# apollo2 register map
Vendor: Ambiq Micro; Series: Apollo; File version: 1.0
CPU: CM4 r1p0, little endian, MPU, FPU, 3 interrupt priority bits
Registers are 32-bit, read-write, reset 0x0 unless marked. A register's access mark holds for its fields unless they carry their own. Offsets are from the block's base; [hi:lo] are bit positions; {n}, {i} and the like mark numbered series; 'fields as' and 'values as' point back to an identical list.

## IOMSTR0 — I2C/SPI Master
Base 0x50004000
Same registers: IOMSTR1 0x50005000, IOMSTR2 0x50006000, IOMSTR3 0x50007000, IOMSTR4 0x50008000, IOMSTR5 0x50009000
0x00 FIFO — FIFO Access Port
  [31:0] FIFO — FIFO access port.
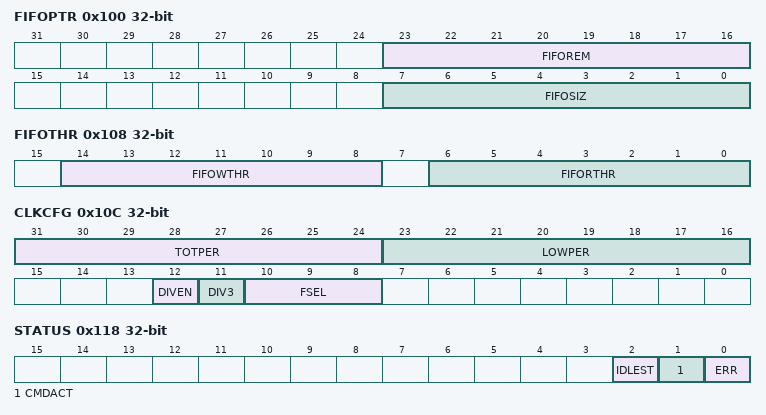
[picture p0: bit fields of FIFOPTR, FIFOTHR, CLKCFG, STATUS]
0x100 FIFOPTR — Current FIFO Pointers
  [23:16] FIFOREM — The number of bytes remaining in the FIFO (i.e. 128-FIFOSIZ if FULLDUP = 0 or 64-FIFOSIZ if FULLDUP = 1)).
  [7:0] FIFOSIZ — The number of bytes currently in the FIFO.
0x104 TLNGTH — Transfer Length
  [11:0] TLNGTH — Remaining transfer length.
0x108 FIFOTHR — FIFO Threshold Configuration
  [14:8] FIFOWTHR — FIFO write threshold.
  [6:0] FIFORTHR — FIFO read threshold.
0x10C CLKCFG — I/O Clock Configuration
  [31:24] TOTPER — Clock total count minus 1.
  [23:16] LOWPER — Clock low count minus 1.
  [12] DIVEN — Enable clock division by TOTPER.
    0=DIS (Disable TOTPER division. value.); 1=EN (Enable TOTPER division. value.)
  [11] DIV3 — Enable divide by 3.
    0=DIS (Select divide by 1. value.); 1=EN (Select divide by 3. value.)
  [10:8] FSEL — Select the input clock frequency.
    0=MIN_PWR (Selects the minimum power clock. This setting should be used whenever the IOMSTR is not active. value.); 1=HFRC (Selects the HFRC as the input clock. value.); 2=HFRC_DIV2 (Selects the HFRC / 2 as the input clock. value.); 3=HFRC_DIV4 (Selects the HFRC / 4 as the input clock. value.); 4=HFRC_DIV8 (Selects the HFRC / 8 as the input clock. value.); 5=HFRC_DIV16 (Selects the HFRC / 16 as the input clock. value.); 6=HFRC_DIV32 (Selects the HFRC / 32 as the input clock. value.); 7=HFRC_DIV64 (Selects the HFRC / 64 as the input clock. value.)
0x110 CMD — Command Register
  [31:0] CMD — This register holds the I/O Command
0x114 CMDRPT — Command Repeat Register
  [4:0] CMDRPT — These bits hold the Command repeat count.
0x118 STATUS
  [2] IDLEST — This bit indicates if the I/O state machine is IDLE.
    1=IDLE (The I/O state machine is in the idle state. value.)
  [1] CMDACT — This bit indicates if the I/O Command is active.
    1=ACTIVE (An I/O command is active. value.)
  [0] ERR — This bit indicates if an error interrupt has occurred.
    1=ERROR (An error has been indicated by the IOM. value.)
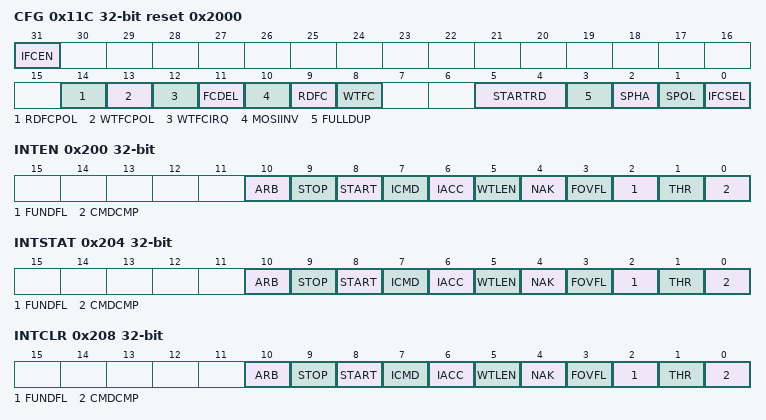
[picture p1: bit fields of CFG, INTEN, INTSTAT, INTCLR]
0x11C CFG reset 0x2000 — I/O Master Configuration
  [31] IFCEN — This bit enables the IO Master.
    0=DIS (Disable the IO Master. value.); 1=EN (Enable the IO Master. value.)
  [14] RDFCPOL — This bit selects the read flow control signal polarity.
    0=HIGH (Flow control signal high creates flow control. value.); 1=LOW (Flow control signal low creates flow control. value.)
  [13] WTFCPOL — This bit selects the write flow control signal polarity.
    values as RDFCPOL
  [12] WTFCIRQ — This bit selects the write mode flow control signal.
    0=MISO (MISO is used as the write mode flow control signal. value.); 1=IRQ (IRQ is used as the write mode flow control signal. value.)
  [11] FCDEL — This bit must be left at the default value of 0.
  [10] MOSIINV — This bit invewrts MOSI when flow control is enabled.
    0=NORMAL (MOSI is set to 0 in read mode and 1 in write mode. value.); 1=INVERT (MOSI is set to 1 in read mode and 0 in write mode. value.)
  [9] RDFC — This bit enables read mode flow control.
    0=DIS (Read mode flow control disabled. value.); 1=EN (Read mode flow control enabled. value.)
  [8] WTFC — This bit enables write mode flow control.
    0=DIS (Write mode flow control disabled. value.); 1=EN (Write mode flow control enabled. value.)
  [5:4] STARTRD — This bit selects the preread timing.
    {v}=PRERD{v} ({v} read delay cycles. value.) (v=0..3)
  [3] FULLDUP — This bit selects full duplex mode.
    0=NORMAL (128 byte FIFO in half duplex mode. value.); 1=FULLDUP (64 byte FIFO in full duplex mode. value.)
  [2] SPHA — This bit selects SPI phase.
    0=SAMPLE_LEADING_EDGE (Sample on the leading (first) clock edge. value.); 1=SAMPLE_TRAILING_EDGE (Sample on the trailing (second) clock edge. value.)
  [1] SPOL — This bit selects SPI polarity.
    0=CLK_BASE_0 (The base value of the clock is 0. value.); 1=CLK_BASE_1 (The base value of the clock is 1. value.)
  [0] IFCSEL — This bit selects the I/O interface.
    0=I2C (Selects I2C interface for the I/O Master. value.); 1=SPI (Selects SPI interface for the I/O Master. value.)
0x200 INTEN — IO Master Interrupts: Enable
  [10] ARB — This is the arbitration loss interrupt. This error occurs if another master collides with an IO Master transfer. Generally, the IOM started an operation but found SDA already low.
  [9] STOP — This is the STOP command interrupt. A STOP bit was detected by the IOM.
  [8] START — This is the START command interrupt. A START from another master was detected. Software must wait for a STOP before proceeding.
  [7] ICMD — This is the illegal command interrupt. Software attempted to issue a CMD while another CMD was already in progress. Or an attempt was made to issue a non-zero-length write CMD with an empty FIFO.
  [6] IACC — This is the illegal FIFO access interrupt. An attempt was made to read the FIFO during a write CMD. Or an attempt was made to write the FIFO on a read CMD.
  [5] WTLEN — This is the WTLEN interrupt.
  [4] NAK — This is the I2C NAK interrupt. The expected ACK from the slave was not received by the IOM.
  [3] FOVFL — This is the Write FIFO Overflow interrupt. An attempt was made to write the FIFO while it was full (i.e. while FIFOSIZ > 124).
  [2] FUNDFL — This is the Read FIFO Underflow interrupt. An attempt was made to read FIFO when empty (i.e. while FIFOSIZ less than 4).
  [1] THR — This is the FIFO Threshold interrupt.
  [0] CMDCMP — This is the Command Complete interrupt.
0x204 INTSTAT — IO Master Interrupts: Status
  fields as INTEN
0x208 INTCLR — IO Master Interrupts: Clear
  fields as INTEN
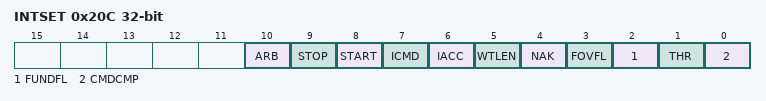
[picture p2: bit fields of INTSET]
0x20C INTSET — IO Master Interrupts: Set
  fields as INTEN
